# CY8C5888LTI_LP097 register map
File version: 0.1
Registers are 8-bit, read-write, no defined reset value unless marked. A register's access mark holds for its fields unless they carry their own. Offsets are from the block's base; [hi:lo] are bit positions; 'fields as' and 'values as' point back to an identical list.

## Timer
Base 0x00000000
0x40006504 Timer_COUNTER 32-bit — UDB.A0 - Current Down Counter Value
0x40006524 Timer_PERIOD 32-bit — UDB.D0 - Assigned Period
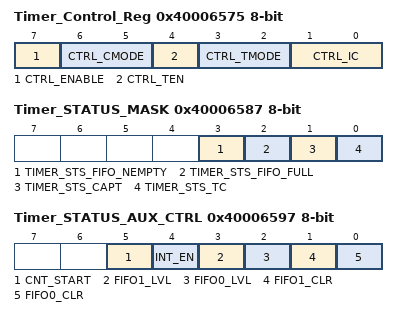
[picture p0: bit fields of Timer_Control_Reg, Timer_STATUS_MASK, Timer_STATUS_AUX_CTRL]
0x40006575 Timer_Control_Reg — UDB Control Register - Assigned Control Register Value
  [7] CTRL_ENABLE — Enable the Timer
  [6:5] CTRL_CMODE — Capture Mode
  [4] CTRL_TEN — Trigger Enable Bit
  [3:2] CTRL_TMODE — Trigger Mode
  [1:0] CTRL_IC — Interrupt Count
0x40006587 Timer_STATUS_MASK — UDB Status bits Interrupt Mask Enable Register
  [3] TIMER_STS_FIFO_NEMPTY ro — FIFO Empty status
  [2] TIMER_STS_FIFO_FULL ro — FIFO Full Status
  [1] TIMER_STS_CAPT ro — Enables the Interrupt on Capture
  [0] TIMER_STS_TC ro — Enables the Interrupt on TC
0x40006597 Timer_STATUS_AUX_CTRL — UDB Auxilliary Control Register
  [5] CNT_START — FIFO0 clear
    0=E_CNT_START0 (Disable counter); 1=E_CNT_START1 (Enable counter)
  [4] INT_EN
    0=E_INT_EN0 (Interrupt disabled); 1=E_INT_EN1 (Interrupt enabled)
  [3] FIFO1_LVL — FIFO level
    0=E_FIFO_LVL_0 (FIFO LVL: input mode: FIFO not full; output mode: FIFO not empty); 1=E_FIFO_LVL_1 (FIFO LVL: input mode: FIFO at least 1/2 empty; output mode: FIFO at least 1/2 full)
  [2] FIFO0_LVL — FIFO level
    values as FIFO1_LVL
  [1] FIFO1_CLR — FIFO1 clear
    0=E_FIFO_CLR_0 (Normal FIFO operation); 1=E_FIFO_CLR_1 (Clear FIFO state)
  [0] FIFO0_CLR — FIFO0 clear
    values as FIFO1_CLR

## PWM_1
Base 0x00000000
0x4000642C PWM_1_COMPARE_Reg 16-bit — UDB.D0 - Assigned Compare Value
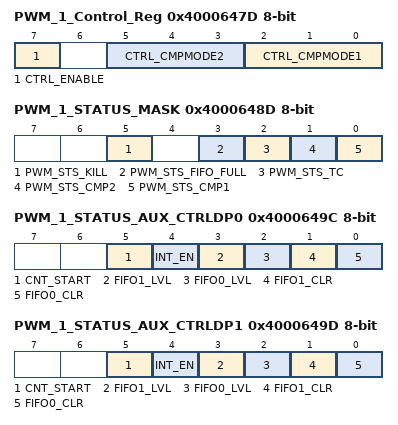
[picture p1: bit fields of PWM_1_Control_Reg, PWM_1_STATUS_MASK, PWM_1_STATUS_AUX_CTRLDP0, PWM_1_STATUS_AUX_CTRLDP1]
0x4000647D PWM_1_Control_Reg — UDB Control Register - Assigned Control Register Value
  [7] CTRL_ENABLE — Enable the PWM
  [5:3] CTRL_CMPMODE2 — Compare mode 2
  [2:0] CTRL_CMPMODE1 — Compare mode 1
0x4000648D PWM_1_STATUS_MASK — UDB Status bits Interrupt Mask Enable Register
  [5] PWM_STS_KILL ro — Enables the Interrupt on Kill
  [3] PWM_STS_FIFO_FULL ro — FIFO Full Status Mask
  [2] PWM_STS_TC ro — Enables the Interrupt on Terminal Count
  [1] PWM_STS_CMP2 ro — Enables the Interrupt on Compare 2
  [0] PWM_STS_CMP1 ro — Enables the Interrupt on Compare 1
0x4000649C PWM_1_STATUS_AUX_CTRLDP0 — UDB Auxilliary Control Register
  [5] CNT_START — FIFO0 clear
    0=E_CNT_START0 (Disable counter); 1=E_CNT_START1 (Enable counter)
  [4] INT_EN
    0=E_INT_EN0 (Interrupt disabled); 1=E_INT_EN1 (Interrupt enabled)
  [3] FIFO1_LVL — FIFO level
    0=E_FIFO_LVL_0 (FIFO LVL: input mode: FIFO not full; output mode: FIFO not empty); 1=E_FIFO_LVL_1 (FIFO LVL: input mode: FIFO at least 1/2 empty; output mode: FIFO at least 1/2 full)
  [2] FIFO0_LVL — FIFO level
    values as FIFO1_LVL
  [1] FIFO1_CLR — FIFO1 clear
    0=E_FIFO_CLR_0 (Normal FIFO operation); 1=E_FIFO_CLR_1 (Clear FIFO state)
  [0] FIFO0_CLR — FIFO0 clear
    values as FIFO1_CLR
0x4000649D PWM_1_STATUS_AUX_CTRLDP1 — UDB Auxilliary Control Register
  fields as PWM_1_STATUS_AUX_CTRLDP0

## QuadDec_1
Base 0x00000000
0x40006400 QuadDec_1_Cnt16_COUNTER 16-bit — Counter value
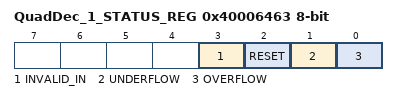
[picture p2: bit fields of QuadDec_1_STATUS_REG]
0x40006463 QuadDec_1_STATUS_REG — Quadrature Decoder Status Register
  [3] INVALID_IN ro — Invalid state transition on the A and B inputs
  [2] RESET ro — Counter Reset due index
  [1] UNDERFLOW ro — Counter underflow
  [0] OVERFLOW ro — Counter overflow

## QuadDec_1_Cnt16
Base 0x00000000; alternate view of QuadDec_1
0x40006400 QuadDec_1_Cnt16_COUNTER 16-bit — UDB.A0 - Current Counter Value
0x40006420 QuadDec_1_Cnt16_PERIOD 16-bit — UDB.D0 - Assigned Period
0x40006430 QuadDec_1_Cnt16_COMPARE 16-bit — UDB.D1 - Assigned Compare Value
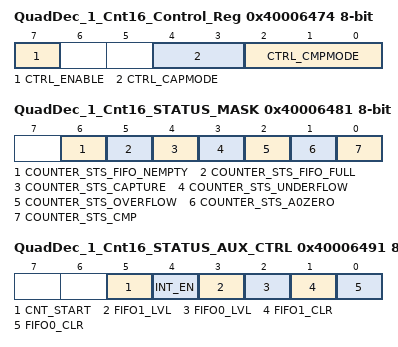
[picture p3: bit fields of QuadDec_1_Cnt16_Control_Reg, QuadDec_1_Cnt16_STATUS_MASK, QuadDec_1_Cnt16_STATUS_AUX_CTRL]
0x40006474 QuadDec_1_Cnt16_Control_Reg — UDB Control Register - Assigned Control Register Value
  [7] CTRL_ENABLE — Enable Counter
  [4:3] CTRL_CAPMODE — Capture mode
  [2:0] CTRL_CMPMODE — Compare mode
0x40006481 QuadDec_1_Cnt16_STATUS_MASK — UDB Status bits Interrupt Mask Enable Register
  [6] COUNTER_STS_FIFO_NEMPTY — FIFO Not Empty Status
  [5] COUNTER_STS_FIFO_FULL — FIFO Full Status
  [4] COUNTER_STS_CAPTURE — Capture Status
  [3] COUNTER_STS_UNDERFLOW — Underflow status
  [2] COUNTER_STS_OVERFLOW — Overflow status
  [1] COUNTER_STS_A0ZERO — A0 Zero ouput status
  [0] COUNTER_STS_CMP — Compare output status
0x40006491 QuadDec_1_Cnt16_STATUS_AUX_CTRL — UDB Auxilliary Control Register
  [5] CNT_START — FIFO0 clear
    0=E_CNT_START0 (Disable counter); 1=E_CNT_START1 (Enable counter)
  [4] INT_EN
    0=E_INT_EN0 (Interrupt disabled); 1=E_INT_EN1 (Interrupt enabled)
  [3] FIFO1_LVL — FIFO level
    0=E_FIFO_LVL_0 (FIFO LVL: input mode: FIFO not full; output mode: FIFO not empty); 1=E_FIFO_LVL_1 (FIFO LVL: input mode: FIFO at least 1/2 empty; output mode: FIFO at least 1/2 full)
  [2] FIFO0_LVL — FIFO level
    values as FIFO1_LVL
  [1] FIFO1_CLR — FIFO1 clear
    0=E_FIFO_CLR_0 (Normal FIFO operation); 1=E_FIFO_CLR_1 (Clear FIFO state)
  [0] FIFO0_CLR — FIFO0 clear
    values as FIFO1_CLR
